# MDR1986VK01 register map
File version: 1.0.2
Registers are 32-bit, read-write, no defined reset value unless marked. A register's access mark holds for its fields unless they carry their own. Offsets are from the block's base; [hi:lo] are bit positions; {n}, {i} and the like mark numbered series.

## MDR_WDT — MDR_WDT description
Base 0x40004000
0x00 KEY — KEY description
0x04 PRL — PRL description
0x08 EN — EN description
0x0C CNT — CNT description

## MDR_FLASH — MDR_FLASH description
Base 0x40006000
0x00 KEY — KEY description
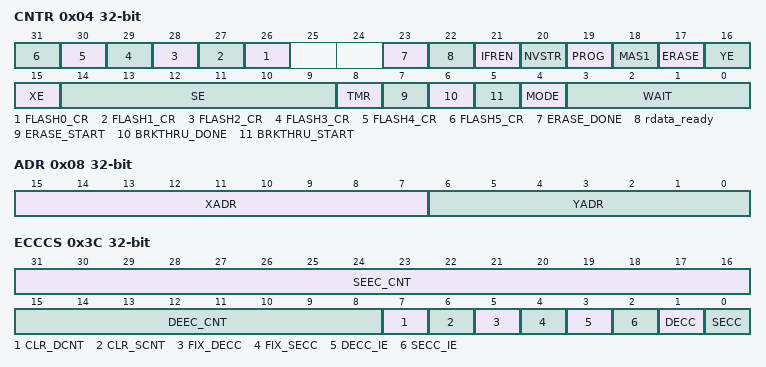
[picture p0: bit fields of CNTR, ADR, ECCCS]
0x04 CNTR — CNTR description
  [n+26] FLASH{n}_CR (n=0..5) — Enable FLASH{n} control from control registers
  [23] ERASE_DONE — FLASH erase completion flag
  [22] rdata_ready — Enable bit for writing read data to registers
  [21] IFREN — Memory type selection bit when accessing memory
  [20] NVSTR
  [19] PROG — Memory programming signal setting bit in register access mode
  [18] MAS1 — Bit for setting the general memory erase signal in the register access mode
  [17] ERASE — Memory erase signal setting bit in register access mode
  [16] YE — Bit for setting the signal to enable the high part of the address in the register access mode
  [15] XE — Bit of formation of the signal of permission of the lower part of the address in the mode of register access
  [14:9] SE — Bits of signal formation of access to EEPROM memory blocks
  [8] TMR — Test mode signal generation bit for EEPROM blocks
  [7] ERASE_START — Beginning of the FLASH erasure procedure, which opens access to FLASH
  [6] BRKTHRU_DONE — Flag of completion of the procedure for accessing a private part of memory
  [5] BRKTHRU_START — The beginning of the procedure for accessing a private part of memory. Self-cleaning bit
  [4] MODE — FLASH access mode. 0 - system access mode; 1 - register-side access mode
  [3:0] WAIT — Number of wait cycles when accessing memory
0x08 ADR — ADR description
  [15:7] XADR — XADR[8:0] = page[5:0], row[2:0]
  [6:0] YADR — col[6:0]
0x0C WDATA3 — WDATA3 description
0x10 WDATA2 — WDATA2 description
0x14 WDATA1 — WDATA1 description
0x18 WDATA0 — WDATA0 description
0x1C WECC0 — WECC0 description
0x20 WECC1 — WECC1 description
0x24 RDATA3 — RDATA3 description
0x28 RDATA2 — RDATA2 description
0x2C RDATA1 — RDATA1 description
0x30 RDATA0 — RDATA0 description
0x34 RECC0 — RECC0 description
0x38 RECC1 — RECC1 description
0x3C ECCCS — ECCCS description
  [31:16] SEEC_CNT — Single error counter
  [15:8] DEEC_CNT — Double error counter
  [7] CLR_DCNT — Single error counter reset bit
  [6] CLR_SCNT — Single error counter reset bit; Write 1 to reset the SECC_CNT counter
  [5] FIX_DECC — Latch enable bit in the address and address data registers of the last error on a double error;0 - allowed
  [4] FIX_SECC — Latch enable bit in the address and address data registers of the last error on a single error;0 - allowed
  [3] DECC_IE — ECC double error interrupt enable bit
  [2] SECC_IE — ECC single error interrupt enable bit
  [1] DECC — Double error flag;Cleared by writing 1
  [0] SECC — Single error flag;Cleared by writing 1
0x40 ECCADR — ECCADR description
0x44 ECCDATA — ECCDATA description
0x48 ECCECC — ECCECC description
0x4C BLOCK — Writing the value 32'hb3c3b3c3 enables the process of opening a closed memory area

## MDR_ROM — MDR_ROM description
Base 0x40005000
Same registers: MDR_RAMC0 0x40008000, MDR_RAMC1 0x40009000, MDR_RAMD0 0x4000A000, MDR_RAMD1 0x4000B000
0x00 KEY — KEY description
0x04 ECCCS — ECCCS description
0x08 ECCADR — ECCADR description
0x0C ECCDATA — ECCDATA description
0x10 ECCECC — ECCECC description
0x14 TEST_TUNING — TEST_TUNING description

## MDR_EBC — MDR_EBC description
Base 0x4000C000
{0x0+0x10*i} RGN{i}_CNTRL (i=0..7) — RGN{i}_CNTRL description
{0x4+0x10*i} RGN{i}_ECCBASE (i=0..7) — RGN{i}_ECCBASE description
{0x8+0x10*i} RGN{i}_ECCS (i=0..7) — RGN{i}_ECCS description
{0xC+0x10*i} RGN{i}_STATE (i=0..7) — RGN{i}_STATE description
0x80 KEY — KEY description
0x84 ECC_ADDR — ECC_ADDR description
0x88 ECC_DATA — ECC_DATA description
0x8C ECC_ECC — ECC_ECC description
0x90 OCLK — OCLK description
